AUTOSAR XML (schema 3.1.2)
package /Components/SWC_AdvCordT
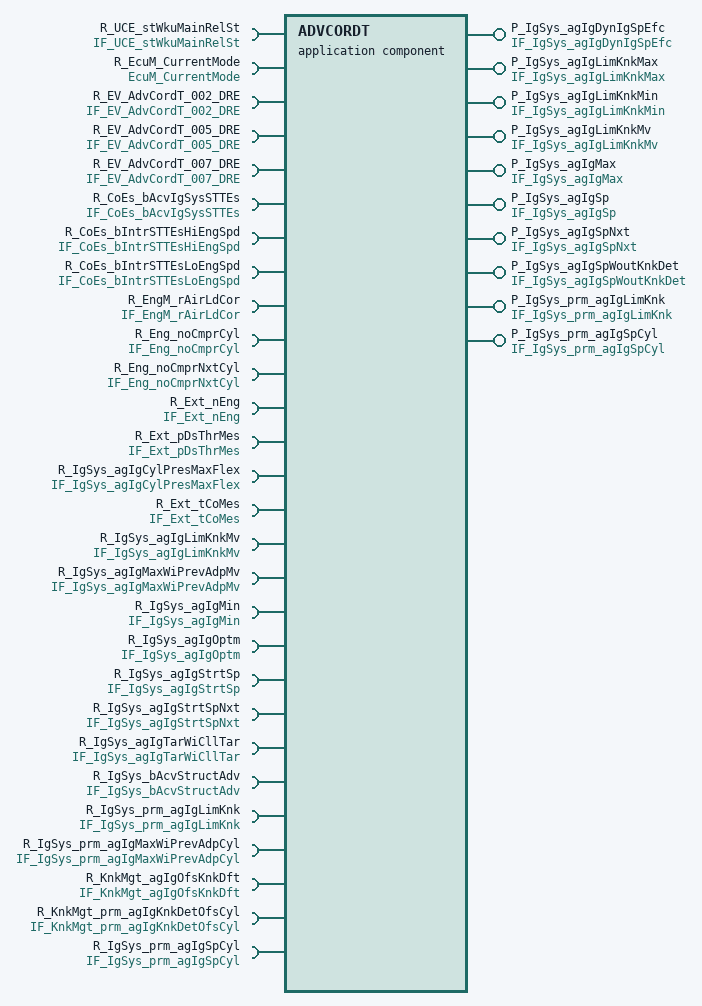
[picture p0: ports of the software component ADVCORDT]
  application software component type ADVCORDT  # AdvCordT
    require port R_UCE_stWkuMainRelSt: required-interface=IF_UCE_stWkuMainRelSt
    10 x provide port:
      P_IgSys_agIgDynIgSpEfc: unqueued-sender-com-spec{data-element=IgSys_agIgDynIgSpEfc, can-invalidate=false, init-value=UInt8InitValue}, provided-interface=IF_IgSys_agIgDynIgSpEfc
      P_IgSys_agIgLimKnkMax: unqueued-sender-com-spec{data-element=IgSys_agIgLimKnkMax, can-invalidate=false, init-value=UInt8InitValue1}, provided-interface=IF_IgSys_agIgLimKnkMax
      P_IgSys_agIgLimKnkMin: unqueued-sender-com-spec{data-element=IgSys_agIgLimKnkMin, can-invalidate=false, init-value=UInt8InitValue3}, provided-interface=IF_IgSys_agIgLimKnkMin
      P_IgSys_agIgLimKnkMv: unqueued-sender-com-spec{data-element=IgSys_agIgLimKnkMv, can-invalidate=false, init-value=UInt8InitValue5}, provided-interface=IF_IgSys_agIgLimKnkMv
      P_IgSys_agIgMax: unqueued-sender-com-spec{data-element=IgSys_agIgMax, can-invalidate=false, init-value=UInt8InitValue7}, provided-interface=IF_IgSys_agIgMax
      P_IgSys_agIgSp: unqueued-sender-com-spec{data-element=IgSys_agIgSp, can-invalidate=false, init-value=UInt8InitValue9}, provided-interface=IF_IgSys_agIgSp
      P_IgSys_agIgSpNxt: unqueued-sender-com-spec{data-element=IgSys_agIgSpNxt, can-invalidate=false, init-value=UInt8InitValue11}, provided-interface=IF_IgSys_agIgSpNxt
      P_IgSys_agIgSpWoutKnkDet: unqueued-sender-com-spec{data-element=IgSys_agIgSpWoutKnkDet, can-invalidate=false, init-value=UInt8InitValue13}, provided-interface=IF_IgSys_agIgSpWoutKnkDet
      P_IgSys_prm_agIgLimKnk: unqueued-sender-com-spec{data-element=IgSys_prm_agIgLimKnk, can-invalidate=false, init-value=rt_Array_UInt8_6InitValue}, provided-interface=IF_IgSys_prm_agIgLimKnk
      P_IgSys_prm_agIgSpCyl: unqueued-sender-com-spec{data-element=IgSys_prm_agIgSpCyl, can-invalidate=false, init-value=rt_Array_UInt8_6InitValue15}, provided-interface=IF_IgSys_prm_agIgSpCyl
    27 x require port:
      R_EcuM_CurrentMode: required-interface=EcuM_CurrentMode
      R_EV_AdvCordT_002_DRE: unqueued-receiver-com-spec{data-element=EV_AdvCordT_002_DRE, init-value=UInt8InitValue17, resync-time=0}, required-interface=IF_EV_AdvCordT_002_DRE
      R_EV_AdvCordT_005_DRE: unqueued-receiver-com-spec{data-element=EV_AdvCordT_005_DRE, init-value=UInt8InitValue19, resync-time=0}, required-interface=IF_EV_AdvCordT_005_DRE
      R_EV_AdvCordT_007_DRE: unqueued-receiver-com-spec{data-element=EV_AdvCordT_007_DRE, init-value=UInt8InitValue21, resync-time=0}, required-interface=IF_EV_AdvCordT_007_DRE
      R_CoEs_bAcvIgSysSTTEs: unqueued-receiver-com-spec{data-element=CoEs_bAcvIgSysSTTEs, init-value=BooleanInitValue, resync-time=0}, required-interface=IF_CoEs_bAcvIgSysSTTEs
      R_CoEs_bIntrSTTEsHiEngSpd: unqueued-receiver-com-spec{data-element=CoEs_bIntrSTTEsHiEngSpd, init-value=BooleanInitValue23, resync-time=0}, required-interface=IF_CoEs_bIntrSTTEsHiEngSpd
      R_CoEs_bIntrSTTEsLoEngSpd: unqueued-receiver-com-spec{data-element=CoEs_bIntrSTTEsLoEngSpd, init-value=BooleanInitValue25, resync-time=0}, required-interface=IF_CoEs_bIntrSTTEsLoEngSpd
      R_EngM_rAirLdCor: unqueued-receiver-com-spec{data-element=EngM_rAirLdCor, init-value=ConstantValue, resync-time=0}, required-interface=IF_EngM_rAirLdCor
      R_Eng_noCmprCyl: unqueued-receiver-com-spec{data-element=Eng_noCmprCyl, init-value=UInt8InitValue27, resync-time=0}, required-interface=IF_Eng_noCmprCyl
      R_Eng_noCmprNxtCyl: unqueued-receiver-com-spec{data-element=Eng_noCmprNxtCyl, init-value=UInt8InitValue29, resync-time=0}, required-interface=IF_Eng_noCmprNxtCyl
      R_Ext_nEng: unqueued-receiver-com-spec{data-element=Ext_nEng, init-value=ConstantValue31, resync-time=0}, required-interface=IF_Ext_nEng
      R_Ext_pDsThrMes: unqueued-receiver-com-spec{data-element=Ext_pDsThrMes, init-value=SInt16InitValue, resync-time=0}, required-interface=IF_Ext_pDsThrMes
      R_IgSys_agIgCylPresMaxFlex: unqueued-receiver-com-spec{data-element=IgSys_agIgCylPresMaxFlex, init-value=UInt8InitValue33, resync-time=0}, required-interface=IF_IgSys_agIgCylPresMaxFlex
      R_Ext_tCoMes: unqueued-receiver-com-spec{data-element=Ext_tCoMes, init-value=ConstantValue35, resync-time=0}, required-interface=IF_Ext_tCoMes
      R_IgSys_agIgLimKnkMv: unqueued-receiver-com-spec{data-element=IgSys_agIgLimKnkMv, init-value=UInt8InitValue37, resync-time=0}, required-interface=IF_IgSys_agIgLimKnkMv
      R_IgSys_agIgMaxWiPrevAdpMv: unqueued-receiver-com-spec{data-element=IgSys_agIgMaxWiPrevAdpMv, init-value=UInt8InitValue39, resync-time=0}, required-interface=IF_IgSys_agIgMaxWiPrevAdpMv
      R_IgSys_agIgMin: unqueued-receiver-com-spec{data-element=IgSys_agIgMin, init-value=UInt8InitValue41, resync-time=0}, required-interface=IF_IgSys_agIgMin
      R_IgSys_agIgOptm: unqueued-receiver-com-spec{data-element=IgSys_agIgOptm, init-value=UInt8InitValue43, resync-time=0}, required-interface=IF_IgSys_agIgOptm
      R_IgSys_agIgStrtSp: unqueued-receiver-com-spec{data-element=IgSys_agIgStrtSp, init-value=UInt8InitValue45, resync-time=0}, required-interface=IF_IgSys_agIgStrtSp
      R_IgSys_agIgStrtSpNxt: unqueued-receiver-com-spec{data-element=IgSys_agIgStrtSpNxt, init-value=UInt8InitValue47, resync-time=0}, required-interface=IF_IgSys_agIgStrtSpNxt
      R_IgSys_agIgTarWiCllTar: unqueued-receiver-com-spec{data-element=IgSys_agIgTarWiCllTar, init-value=UInt8InitValue49, resync-time=0}, required-interface=IF_IgSys_agIgTarWiCllTar
      R_IgSys_bAcvStructAdv: unqueued-receiver-com-spec{data-element=IgSys_bAcvStructAdv, init-value=BooleanInitValue51, resync-time=0}, required-interface=IF_IgSys_bAcvStructAdv
      R_IgSys_prm_agIgLimKnk: unqueued-receiver-com-spec{data-element=IgSys_prm_agIgLimKnk, init-value=rt_Array_UInt8_6InitValue, resync-time=0}, required-interface=IF_IgSys_prm_agIgLimKnk
      R_IgSys_prm_agIgMaxWiPrevAdpCyl: unqueued-receiver-com-spec{data-element=IgSys_prm_agIgMaxWiPrevAdpCyl, init-value=rt_Array_UInt8_6InitValue53, resync-time=0}, required-interface=IF_IgSys_prm_agIgMaxWiPrevAdpCyl
      R_KnkMgt_agIgOfsKnkDft: unqueued-receiver-com-spec{data-element=KnkMgt_agIgOfsKnkDft, init-value=UInt8InitValue55, resync-time=0}, required-interface=IF_KnkMgt_agIgOfsKnkDft
      R_KnkMgt_prm_agIgKnkDetOfsCyl: unqueued-receiver-com-spec{data-element=KnkMgt_prm_agIgKnkDetOfsCyl, init-value=rt_Array_UInt8_6InitValue57, resync-time=0}, required-interface=IF_KnkMgt_prm_agIgKnkDetOfsCyl
      R_IgSys_prm_agIgSpCyl: unqueued-receiver-com-spec{data-element=IgSys_prm_agIgSpCyl, init-value=rt_Array_UInt8_6InitValue59, resync-time=0}, required-interface=IF_IgSys_prm_agIgSpCyl
  45 x constant specification:
    BooleanInitValue
      value:
        boolean literal BooleanInitValue: type=DT_CoEs_bAcvIgSysSTTEs, value=false
    BooleanInitValue23
      value:
        boolean literal BooleanInitValue23: type=DT_CoEs_bIntrSTTEsHiEngSpd, value=false
    BooleanInitValue25
      value:
        boolean literal BooleanInitValue25: type=DT_CoEs_bIntrSTTEsLoEngSpd, value=false
    BooleanInitValue51
      value:
        boolean literal BooleanInitValue51: type=DT_IgSys_bAcvStructAdv, value=false
    ConstantValue
      value:
        integer literal ConstantValue: type=DT_EngM_rAirLdCor, value=0
    ConstantValue31
      value:
        integer literal ConstantValue31: type=DT_Ext_nEng, value=0
    ConstantValue35
      value:
        integer literal ConstantValue35: type=DT_Ext_tCoMes, value=20
    InitValue_UInt16_0
      value:
        integer literal InitValue_UInt16_0: type=DT_IgSys_agIgOfsTest_irv, value=0
    InitValue_UInt8_0
      value:
        integer literal InitValue_UInt8_0: type=DT_IgSys_agIgMaxWiPrevAdpCyl_irv, value=0
    InitValue_UInt8_061
      value:
        integer literal InitValue_UInt8_061: type=DT_IgSys_agIgTest_irv, value=0
    InitValue_UInt8_063
      value:
        integer literal InitValue_UInt8_063: type=DT_IgSys_prm_agIgTestCyl_003_irv, value=0
    InitValue_UInt8_065
      value:
        integer literal InitValue_UInt8_065: type=DT_IgSys_prm_agIgTestCyl_001_irv, value=0
    InitValue_UInt8_067
      value:
        integer literal InitValue_UInt8_067: type=DT_IgSys_prm_agIgTestCyl_002_irv, value=0
    InitValue_UInt8_069
      value:
        integer literal InitValue_UInt8_069: type=DT_IgSys_agIgOfsPrev_irv, value=0
    InitValue_UInt8_071
      value:
        integer literal InitValue_UInt8_071: type=DT_IgSys_prm_agIgTestCyl_006_irv, value=0
    InitValue_UInt8_073
      value:
        integer literal InitValue_UInt8_073: type=DT_IgSys_prm_agIgTestCyl_005_irv, value=0
    InitValue_UInt8_075
      value:
        integer literal InitValue_UInt8_075: type=DT_IgSys_prm_agIgTestCyl_004_irv, value=0
    rt_Array_UInt8_6InitValue
      value:
        array specification rt_Array_UInt8_6InitValue: type=rt_Array_UInt8_6_m0
          6 x integer literal, all with type=DT_IgSys_prm_agIgLimKnk, value=96:
            UInt8_{1..6}
    rt_Array_UInt8_6InitValue15
      value:
        array specification rt_Array_UInt8_6InitValue15: type=rt_Array_UInt8_6_m1
          6 x integer literal, all with type=DT_IgSys_prm_agIgSpCyl, value=96:
            UInt8_{1..6}
    rt_Array_UInt8_6InitValue53
      value:
        array specification rt_Array_UInt8_6InitValue53: type=rt_Array_UInt8_6_m2
          6 x integer literal, all with type=DT_IgSys_prm_agIgMaxWiPrevAdpCyl, value=255:
            UInt8_{1..6}
    rt_Array_UInt8_6InitValue57
      value:
        array specification rt_Array_UInt8_6InitValue57: type=rt_Array_UInt8_6_m3
          6 x integer literal, all with type=DT_KnkMgt_prm_agIgKnkDetOfsCyl, value=0:
            UInt8_{1..6}
    rt_Array_UInt8_6InitValue59
      value:
        array specification rt_Array_UInt8_6InitValue59: type=rt_Array_UInt8_6_m1
          6 x integer literal, all with type=DT_IgSys_prm_agIgSpCyl, value=96:
            UInt8_{1..6}
    SInt16InitValue
      value:
        integer literal SInt16InitValue: type=DT_Ext_pDsThrMes, value=1000
    UInt8InitValue
      value:
        integer literal UInt8InitValue: type=DT_IgSys_agIgDynIgSpEfc, value=96
    UInt8InitValue1
      value:
        integer literal UInt8InitValue1: type=DT_IgSys_agIgLimKnkMax, value=96
    UInt8InitValue11
      value:
        integer literal UInt8InitValue11: type=DT_IgSys_agIgSpNxt, value=96
    UInt8InitValue13
      value:
        integer literal UInt8InitValue13: type=DT_IgSys_agIgSpWoutKnkDet, value=192
    UInt8InitValue17
      value:
        integer literal UInt8InitValue17: type=DT_EV_AdvCordT_002_DRE, value=0
    UInt8InitValue19
      value:
        integer literal UInt8InitValue19: type=DT_EV_AdvCordT_005_DRE, value=0
    UInt8InitValue21
      value:
        integer literal UInt8InitValue21: type=DT_EV_AdvCordT_007_DRE, value=0
    UInt8InitValue27
      value:
        integer literal UInt8InitValue27: type=DT_Eng_noCmprCyl, value=1
    UInt8InitValue29
      value:
        integer literal UInt8InitValue29: type=DT_Eng_noCmprNxtCyl, value=1
    UInt8InitValue3
      value:
        integer literal UInt8InitValue3: type=DT_IgSys_agIgLimKnkMin, value=192
    UInt8InitValue33
      value:
        integer literal UInt8InitValue33: type=DT_IgSys_agIgCylPresMaxFlex, value=255
    UInt8InitValue37
      value:
        integer literal UInt8InitValue37: type=DT_IgSys_agIgLimKnkMv, value=96
    UInt8InitValue39
      value:
        integer literal UInt8InitValue39: type=DT_IgSys_agIgMaxWiPrevAdpMv, value=255
    UInt8InitValue41
      value:
        integer literal UInt8InitValue41: type=DT_IgSys_agIgMin, value=0
    UInt8InitValue43
      value:
        integer literal UInt8InitValue43: type=DT_IgSys_agIgOptm, value=149
    UInt8InitValue45
      value:
        integer literal UInt8InitValue45: type=DT_IgSys_agIgStrtSp, value=0
    UInt8InitValue47
      value:
        integer literal UInt8InitValue47: type=DT_IgSys_agIgStrtSpNxt, value=0
    UInt8InitValue49
      value:
        integer literal UInt8InitValue49: type=DT_IgSys_agIgTarWiCllTar, value=150
    UInt8InitValue5
      value:
        integer literal UInt8InitValue5: type=DT_IgSys_agIgLimKnkMv, value=96
    UInt8InitValue55
      value:
        integer literal UInt8InitValue55: type=DT_KnkMgt_agIgOfsKnkDft, value=0
    UInt8InitValue7
      value:
        integer literal UInt8InitValue7: type=DT_IgSys_agIgMax, value=96
    UInt8InitValue9
      value:
        integer literal UInt8InitValue9: type=DT_IgSys_agIgSp, value=96
  internal behavior IB_AdvCordT: component=ADVCORDT
    data received event EV_AdvCordT_002_DRE: mode-dependency=dependent-on-mode=[R_UCE_stWkuMainRelSt.RCD_stWkuMainRelSt.PreMainWakeUp, R_UCE_stWkuMainRelSt.RCD_stWkuMainRelSt.PostMainWakeUp, R_UCE_stWkuMainRelSt.RCD_stWkuMainRelSt.Invalid], start-on-event=RE_AdvCordT_002_DRE, data=R_EV_AdvCordT_002_DRE.EV_AdvCordT_002_DRE
    mode switch event EV_AdvCordT_001_MSE: start-on-event=RE_AdvCordT_001_MSE, activation=ENTRY, mode=R_EcuM_CurrentMode.currentMode.RUN
    data received event EV_AdvCordT_007_DRE: mode-dependency=dependent-on-mode=[R_UCE_stWkuMainRelSt.RCD_stWkuMainRelSt.PreMainWakeUp, R_UCE_stWkuMainRelSt.RCD_stWkuMainRelSt.PostMainWakeUp, R_UCE_stWkuMainRelSt.RCD_stWkuMainRelSt.Invalid], start-on-event=RE_AdvCordT_007_DRE, data=R_EV_AdvCordT_007_DRE.EV_AdvCordT_007_DRE
    mode switch event EV_AdvCordT_003_MSE: start-on-event=RE_AdvCordT_003_MSE, activation=ENTRY, mode=R_EcuM_CurrentMode.currentMode.RUN
    data received event EV_AdvCordT_005_DRE: mode-dependency=dependent-on-mode=[R_UCE_stWkuMainRelSt.RCD_stWkuMainRelSt.PreMainWakeUp, R_UCE_stWkuMainRelSt.RCD_stWkuMainRelSt.PostMainWakeUp, R_UCE_stWkuMainRelSt.RCD_stWkuMainRelSt.Invalid], start-on-event=RE_AdvCordT_005_DRE, data=R_EV_AdvCordT_005_DRE.EV_AdvCordT_005_DRE
    10 x inter runnable variable, all with sw-calibration-access=READ-WRITE, communication-approach=EXPLICIT:
      IgSys_agIgOfsTest_irv: type=DT_IgSys_agIgOfsTest_irv, init-value=InitValue_UInt16_0
      IgSys_agIgMaxWiPrevAdpCyl_irv: type=DT_IgSys_agIgMaxWiPrevAdpCyl_irv, init-value=InitValue_UInt8_0
      IgSys_prm_agIgTestCyl_002_irv: type=DT_IgSys_prm_agIgTestCyl_002_irv, init-value=InitValue_UInt8_067
      IgSys_prm_agIgTestCyl_005_irv: type=DT_IgSys_prm_agIgTestCyl_005_irv, init-value=InitValue_UInt8_073
      IgSys_prm_agIgTestCyl_003_irv: type=DT_IgSys_prm_agIgTestCyl_003_irv, init-value=InitValue_UInt8_063
      IgSys_agIgTest_irv: type=DT_IgSys_agIgTest_irv, init-value=InitValue_UInt8_061
      IgSys_agIgOfsPrev_irv: type=DT_IgSys_agIgOfsPrev_irv, init-value=InitValue_UInt8_069
      IgSys_prm_agIgTestCyl_001_irv: type=DT_IgSys_prm_agIgTestCyl_001_irv, init-value=InitValue_UInt8_065
      IgSys_prm_agIgTestCyl_006_irv: type=DT_IgSys_prm_agIgTestCyl_006_irv, init-value=InitValue_UInt8_071
      IgSys_prm_agIgTestCyl_004_irv: type=DT_IgSys_prm_agIgTestCyl_004_irv, init-value=InitValue_UInt8_075
    5 x runnable:
      RE_AdvCordT_003_MSE: written-variable=[IgSys_agIgOfsPrev_irv, IgSys_agIgMaxWiPrevAdpCyl_irv]
        10 x data send point:
          ds_IgSys_prm_agIgSpCyl: data-element=P_IgSys_prm_agIgSpCyl.IgSys_prm_agIgSpCyl
          ds_IgSys_agIgSpWoutKnkDet: data-element=P_IgSys_agIgSpWoutKnkDet.IgSys_agIgSpWoutKnkDet
          ds_IgSys_agIgLimKnkMin: data-element=P_IgSys_agIgLimKnkMin.IgSys_agIgLimKnkMin
          ds_IgSys_agIgLimKnkMax: data-element=P_IgSys_agIgLimKnkMax.IgSys_agIgLimKnkMax
          ds_IgSys_agIgSpNxt: data-element=P_IgSys_agIgSpNxt.IgSys_agIgSpNxt
          ds_IgSys_agIgLimKnkMv: data-element=P_IgSys_agIgLimKnkMv.IgSys_agIgLimKnkMv
          ds_IgSys_agIgDynIgSpEfc: data-element=P_IgSys_agIgDynIgSpEfc.IgSys_agIgDynIgSpEfc
          ds_IgSys_agIgMax: data-element=P_IgSys_agIgMax.IgSys_agIgMax
          ds_IgSys_agIgSp: data-element=P_IgSys_agIgSp.IgSys_agIgSp
          ds_IgSys_prm_agIgLimKnk: data-element=P_IgSys_prm_agIgLimKnk.IgSys_prm_agIgLimKnk
      RE_AdvCordT_007_DRE: written-variable=IgSys_agIgMaxWiPrevAdpCyl_irv
        8 x data receive point:
          dr_Eng_noCmprCyl: data-element=R_Eng_noCmprCyl.Eng_noCmprCyl
          dr_KnkMgt_prm_agIgKnkDetOfsCyl: data-element=R_KnkMgt_prm_agIgKnkDetOfsCyl.KnkMgt_prm_agIgKnkDetOfsCyl
          dr_KnkMgt_agIgOfsKnkDft: data-element=R_KnkMgt_agIgOfsKnkDft.KnkMgt_agIgOfsKnkDft
          dr_IgSys_agIgOptm: data-element=R_IgSys_agIgOptm.IgSys_agIgOptm
          dr_EV_AdvCordT_007_DRE: data-element=R_EV_AdvCordT_007_DRE.EV_AdvCordT_007_DRE
          dr_IgSys_agIgMaxWiPrevAdpMv: data-element=R_IgSys_agIgMaxWiPrevAdpMv.IgSys_agIgMaxWiPrevAdpMv
          dr_IgSys_prm_agIgMaxWiPrevAdpCyl: data-element=R_IgSys_prm_agIgMaxWiPrevAdpCyl.IgSys_prm_agIgMaxWiPrevAdpCyl
          dr_IgSys_agIgCylPresMaxFlex: data-element=R_IgSys_agIgCylPresMaxFlex.IgSys_agIgCylPresMaxFlex
        5 x data send point:
          ds_IgSys_agIgMax: data-element=P_IgSys_agIgMax.IgSys_agIgMax
          ds_IgSys_agIgLimKnkMv: data-element=P_IgSys_agIgLimKnkMv.IgSys_agIgLimKnkMv
          ds_IgSys_prm_agIgLimKnk: data-element=P_IgSys_prm_agIgLimKnk.IgSys_prm_agIgLimKnk
          ds_IgSys_agIgLimKnkMax: data-element=P_IgSys_agIgLimKnkMax.IgSys_agIgLimKnkMax
          ds_IgSys_agIgLimKnkMin: data-element=P_IgSys_agIgLimKnkMin.IgSys_agIgLimKnkMin
      RE_AdvCordT_002_DRE: read-variable=[IgSys_agIgTest_irv, IgSys_agIgOfsTest_irv, IgSys_prm_agIgTestCyl_005_irv, IgSys_prm_agIgTestCyl_006_irv, IgSys_prm_agIgTestCyl_002_irv, IgSys_prm_agIgTestCyl_003_irv, IgSys_prm_agIgTestCyl_001_irv, IgSys_prm_agIgTestCyl_004_irv], written-variable=[IgSys_agIgTest_irv, IgSys_agIgOfsTest_irv, IgSys_prm_agIgTestCyl_005_irv, IgSys_prm_agIgTestCyl_006_irv, IgSys_prm_agIgTestCyl_002_irv, IgSys_prm_agIgTestCyl_003_irv, IgSys_prm_agIgTestCyl_001_irv, IgSys_prm_agIgTestCyl_004_irv]
        5 x data receive point:
          dr_EV_AdvCordT_002_DRE: data-element=R_EV_AdvCordT_002_DRE.EV_AdvCordT_002_DRE
          dr_Ext_pDsThrMes: data-element=R_Ext_pDsThrMes.Ext_pDsThrMes
          dr_Ext_nEng: data-element=R_Ext_nEng.Ext_nEng
          dr_EngM_rAirLdCor: data-element=R_EngM_rAirLdCor.EngM_rAirLdCor
          dr_IgSys_bAcvStructAdv: data-element=R_IgSys_bAcvStructAdv.IgSys_bAcvStructAdv
      RE_AdvCordT_001_MSE: written-variable=[IgSys_agIgTest_irv, IgSys_prm_agIgTestCyl_006_irv, IgSys_prm_agIgTestCyl_004_irv, IgSys_prm_agIgTestCyl_005_irv, IgSys_prm_agIgTestCyl_002_irv, IgSys_prm_agIgTestCyl_003_irv, IgSys_prm_agIgTestCyl_001_irv, IgSys_agIgOfsTest_irv]
      RE_AdvCordT_005_DRE: read-variable=[IgSys_prm_agIgTestCyl_006_irv, IgSys_agIgOfsTest_irv, IgSys_prm_agIgTestCyl_004_irv, IgSys_prm_agIgTestCyl_003_irv, IgSys_agIgTest_irv, IgSys_prm_agIgTestCyl_001_irv, IgSys_prm_agIgTestCyl_005_irv, IgSys_agIgMaxWiPrevAdpCyl_irv, IgSys_prm_agIgTestCyl_002_irv, IgSys_agIgOfsPrev_irv], written-variable=IgSys_agIgOfsPrev_irv
        18 x data receive point:
          dr_CoEs_bIntrSTTEsLoEngSpd: data-element=R_CoEs_bIntrSTTEsLoEngSpd.CoEs_bIntrSTTEsLoEngSpd
          dr_IgSys_agIgStrtSp: data-element=R_IgSys_agIgStrtSp.IgSys_agIgStrtSp
          dr_CoEs_bAcvIgSysSTTEs: data-element=R_CoEs_bAcvIgSysSTTEs.CoEs_bAcvIgSysSTTEs
          dr_EV_AdvCordT_005_DRE: data-element=R_EV_AdvCordT_005_DRE.EV_AdvCordT_005_DRE
          dr_IgSys_agIgStrtSpNxt: data-element=R_IgSys_agIgStrtSpNxt.IgSys_agIgStrtSpNxt
          dr_IgSys_prm_agIgSpCyl: data-element=R_IgSys_prm_agIgSpCyl.IgSys_prm_agIgSpCyl
          dr_CoEs_bIntrSTTEsHiEngSpd: data-element=R_CoEs_bIntrSTTEsHiEngSpd.CoEs_bIntrSTTEsHiEngSpd
          dr_IgSys_agIgMin: data-element=R_IgSys_agIgMin.IgSys_agIgMin
          dr_Eng_noCmprNxtCyl: data-element=R_Eng_noCmprNxtCyl.Eng_noCmprNxtCyl
          dr_IgSys_agIgLimKnkMv: data-element=R_IgSys_agIgLimKnkMv.IgSys_agIgLimKnkMv
          dr_IgSys_bAcvStructAdv: data-element=R_IgSys_bAcvStructAdv.IgSys_bAcvStructAdv
          dr_KnkMgt_agIgOfsKnkDft: data-element=R_KnkMgt_agIgOfsKnkDft.KnkMgt_agIgOfsKnkDft
          dr_Eng_noCmprCyl: data-element=R_Eng_noCmprCyl.Eng_noCmprCyl
          dr_IgSys_agIgTarWiCllTar: data-element=R_IgSys_agIgTarWiCllTar.IgSys_agIgTarWiCllTar
          dr_KnkMgt_prm_agIgKnkDetOfsCyl: data-element=R_KnkMgt_prm_agIgKnkDetOfsCyl.KnkMgt_prm_agIgKnkDetOfsCyl
          dr_IgSys_agIgCylPresMaxFlex: data-element=R_IgSys_agIgCylPresMaxFlex.IgSys_agIgCylPresMaxFlex
          dr_IgSys_prm_agIgLimKnk: data-element=R_IgSys_prm_agIgLimKnk.IgSys_prm_agIgLimKnk
          dr_Ext_tCoMes: data-element=R_Ext_tCoMes.Ext_tCoMes
        5 x data send point:
          ds_IgSys_agIgDynIgSpEfc: data-element=P_IgSys_agIgDynIgSpEfc.IgSys_agIgDynIgSpEfc
          ds_IgSys_agIgSpWoutKnkDet: data-element=P_IgSys_agIgSpWoutKnkDet.IgSys_agIgSpWoutKnkDet
          ds_IgSys_prm_agIgSpCyl: data-element=P_IgSys_prm_agIgSpCyl.IgSys_prm_agIgSpCyl
          ds_IgSys_agIgSp: data-element=P_IgSys_agIgSp.IgSys_agIgSp
          ds_IgSys_agIgSpNxt: data-element=P_IgSys_agIgSpNxt.IgSys_agIgSpNxt
  swc implementation Imp_AdvCordT: code-generator=Real-Time Workshop Embedded Coder 5.5 (R2010a) 25-Jan-2010, programming-language=C, behavior=IB_AdvCordT
    code-descriptors:
      code CodeDescriptor: type=SRC
        10 x xfile:
          AdvCordT_private_h: url=AdvCordT_private.h
          AdvCordT_Version_c: url=AdvCordT_Version.c
          AdvCordT_data_c: url=AdvCordT_data.c
          AdvCordT_c: url=AdvCordT.c
          AdvCordT_h: url=AdvCordT.h
          AdvCordT_import_h: url=AdvCordT_import.h
          AdvCordT_Version_h: url=AdvCordT_Version.h
          AdvCordT_MemMap_h: url=AdvCordT_MemMap.h
          AdvCordT_types_h: url=AdvCordT_types.h
          AdvCordT_Def_c: url=AdvCordT_Def.c
package /Components/SWC_AdvCordT/AdvCordT_IRVDatatypes
  10 x integer type, all with lower-limit=0:
    DT_IgSys_agIgMaxWiPrevAdpCyl_irv: base-type=uint8, upper-limit=255
    DT_IgSys_agIgOfsPrev_irv: base-type=uint8, upper-limit=255
    DT_IgSys_agIgOfsTest_irv: base-type=uint16, upper-limit=65535
    DT_IgSys_agIgTest_irv: base-type=uint8, upper-limit=255
    DT_IgSys_prm_agIgTestCyl_{001..006}_irv: base-type=uint8, upper-limit=255
